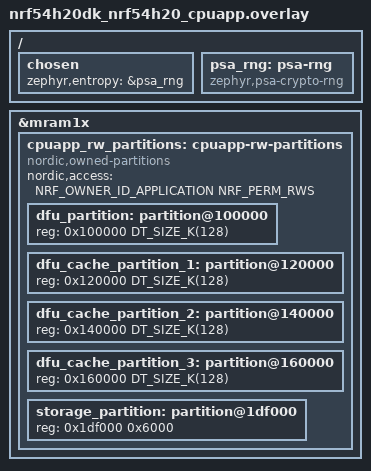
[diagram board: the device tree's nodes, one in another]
/*
 * Copyright (c) 2024 Nordic Semiconductor ASA
 *
 * SPDX-License-Identifier: LicenseRef-Nordic-5-Clause
 */

/ {
	chosen {
		zephyr,entropy = &psa_rng;
	};

	psa_rng: psa-rng {
		compatible = "zephyr,psa-crypto-rng";
		status = "okay";
	};
};

/* Split DFU partition into a smaller one and DFU caches. */
/delete-node/ &dfu_partition;
/delete-node/ &storage_partition;

&mram1x {
	cpuapp_rw_partitions: cpuapp-rw-partitions {
		compatible = "nordic,owned-partitions", "fixed-partitions";
		status = "okay";
		nordic,access = <NRF_OWNER_ID_APPLICATION NRF_PERM_RWS>;
		#address-cells = < 0x1 >;
		#size-cells = < 0x1 >;

		dfu_partition: partition@100000 {
			reg = < 0x100000 DT_SIZE_K(128) >;
		};

		dfu_cache_partition_1: partition@120000 {
			reg = <0x120000 DT_SIZE_K(128)>;
		};

		dfu_cache_partition_2: partition@140000 {
			reg = <0x140000 DT_SIZE_K(128)>;
		};

		dfu_cache_partition_3: partition@160000 {
			reg = <0x160000 DT_SIZE_K(128)>;
		};

		storage_partition: partition@1df000 {
			reg = < 0x1df000 0x6000 >;
		};
	};
};
